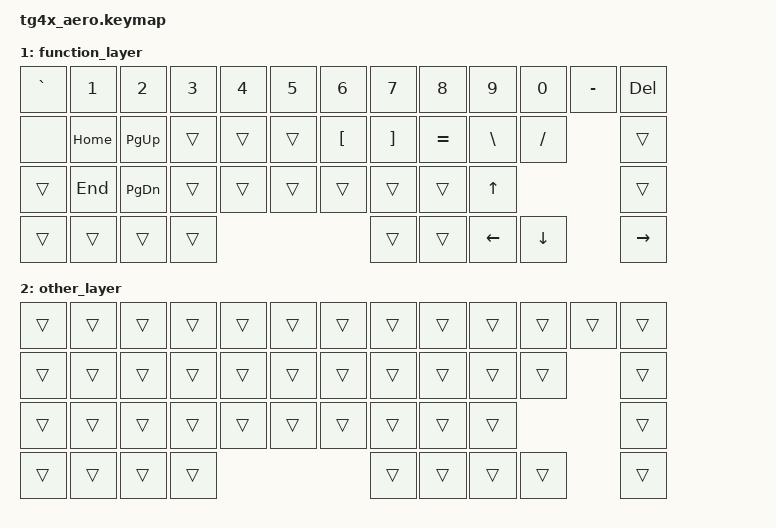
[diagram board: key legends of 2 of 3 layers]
/*
 * Copyright (c) 2020 The ZMK Contributors
 *
 * SPDX-License-Identifier: MIT
 */

#include <behaviors.dtsi>
#include <dt-bindings/zmk/keys.h>
#include <dt-bindings/zmk/bt.h>

/ {
    behaviors {
        ht: hold_tap {
            compatible = "zmk,behavior-hold-tap";
            #binding-cells = <2>;
            tapping-term-ms = <200>;
            flavor = "tap-preferred";
            bindings = <&kp>, <&kp>;
        };
    };

    keymap {
        compatible = "zmk,keymap";

  [_BL] = LAYOUT_SPLIT_ANSI( /* Base */
        default_layer {
            bindings = <
&kp ESC      &kp Q       &kp W        &kp E    &kp R        &kp T     &kp Y    &kp U    &kp I     &kp O    &kp P    &kp SEMI  &kp BSPC
&kp TAB      &kp A       &kp S        &kp D    &kp F        &kp G     &kp H    &kp J    &kp K     &kp L    &kp APOS           &kp RET
&kp LSHFT    &kp Z       &kp X        &kp C    &kp V        &kp B     &kp N    &kp M    &kp COMMA &kp DOT  &kp Q              &kp RSHFT
&kp LCTRL    &kp LGUI    &kp LALT     &kp LALT         &kp SPACE    &kp SPACE             &kp RALT  &kp RGUI &mo 2          &kp RCTRL
            >;
        };

        function_layer {
            bindings = <
&kp GRAVE       &kp N1   &kp N2    &kp N3 &kp N4 &kp N5 &kp N6   &kp N7   &kp N8    &kp N9    &kp N0   &kp MINUS &kp DEL
&none           &kp HOME &kp PG_UP &trans &trans &trans &kp LBKT &kp RBKT &kp EQUAL &kp BSLH  &kp FSLH           &trans
&trans          &kp END  &kp PG_DN &trans &trans &trans &trans   &trans   &trans    &kp UP                       &trans
&trans          &trans   &trans    &trans                        &trans   &trans    &kp LEFT  &kp DOWN           &kp RIGHT
            >;
        };

        other_layer {
            bindings = <
&trans    &trans    &trans    &trans    &trans    &trans    &trans    &trans    &trans    &trans    &trans    &trans      &trans
&trans    &trans    &trans    &trans    &trans    &trans    &trans    &trans    &trans    &trans    &trans    &trans
&trans    &trans    &trans    &trans    &trans    &trans    &trans    &trans    &trans    &trans    &trans
&trans    &trans    &trans    &trans    &trans    &trans    &trans    &trans    &trans
            >;
        };

    };
};
